# PIC32CZ4010CA80144 device description
Architecture: CORTEX-M7; Family: PIC32C; Series: PIC32CZCA80
Registers are 32-bit, read-write, reset 0x0 unless marked. A register's access mark holds for its fields unless they carry their own. Offsets are from the block's base; [hi:lo] are bit positions; {n}, {i} and the like mark numbered series; 'fields as' and 'values as' point back to an identical list.

## EIC — External Interrupt Controller
Instances: EIC 0x44800000
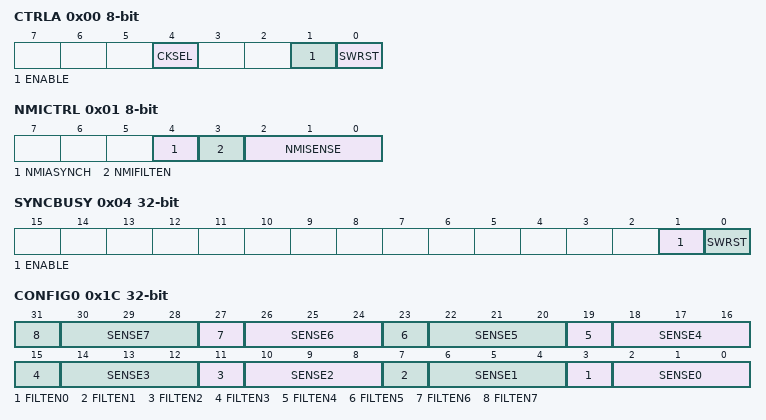
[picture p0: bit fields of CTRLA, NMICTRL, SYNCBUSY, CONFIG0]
0x00 CTRLA 8-bit — Control A
  [4] CKSEL — Clock Selection
    0=CLK_GCLK (Clocked by GCLK); 1=CLK_ULP32K (Clocked by ULP32K)
  [1] ENABLE
  [0] SWRST — Software Reset
0x01 NMICTRL 8-bit — Non-Maskable Interrupt Control
  [4] NMIASYNCH — Asynchronous Edge Detection Mode
    0=SYNC (Edge detection is clock synchronously operated); 1=ASYNC (Edge detection is clock asynchronously operated)
  [3] NMIFILTEN — Non-Maskable Interrupt Filter Enable
  [2:0] NMISENSE — Non-Maskable Interrupt Sense Configuration
    0=NONE (No detection); 1=RISE (Rising-edge detection); 2=FALL (Falling-edge detection); 3=BOTH (Both-edges detection); 4=HIGH (High-level detection); 5=LOW (Low-level detection)
0x02 NMIFLAG 16-bit (atomic clear) — Non-Maskable Interrupt Flag Status and Clear
  [0] NMI — Non-Maskable Interrupt
0x04 SYNCBUSY ro — Synchronization Busy
  [1] ENABLE — Enable Synchronization Busy Status
  [0] SWRST — Software Reset Synchronization Busy Status
0x08 EVCTRL — Event Control
  [15:0] EXTINTEO — External Interrupt Event Output Enable
0x0C INTENCLR (atomic clear) — Interrupt Enable Clear
  [15:0] EXTINT — External Interrupt Enable
0x10 INTENSET (atomic set) — Interrupt Enable Set
  [15:0] EXTINT — External Interrupt Enable
0x14 INTFLAG (atomic clear) — Interrupt Flag Status and Clear
  [15:0] EXTINT — External Interrupt
0x18 ASYNCH — External Interrupt Asynchronous Mode
  [15:0] ASYNCH — Asynchronous Edge Detection Mode
    values as NMICTRL.NMIASYNCH
0x1C CONFIG0 — External Interrupt Sense Configuration
  [4n+3] FILTEN{n} (n=0..7) — Filter Enable {n}
  [4n+2:4n] SENSE{n} (n=0..7) — Input Sense Configuration {n}
    0=NONE (No detection); 1=RISE (Rising edge detection); 2=FALL (Falling edge detection); 3=BOTH (Both edges detection); 4=HIGH (High level detection); 5=LOW (Low level detection)
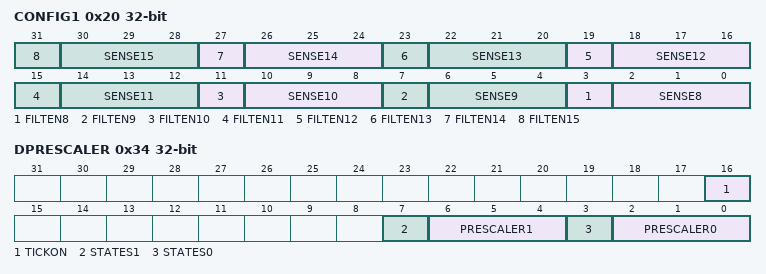
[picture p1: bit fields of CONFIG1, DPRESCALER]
0x20 CONFIG1 — External Interrupt Sense Configuration
  [4n-29] FILTEN{n} (n=8..15) — Filter Enable {n}
  [4n-30:4n-32] SENSE{n} (n=8..15) — Input Sense Configuration {n}
    values as CONFIG0.SENSE0
0x30 DEBOUNCEN — Debouncer Enable
  [15:0] DEBOUNCEN
0x34 DPRESCALER — Debouncer Prescaler
  [16] TICKON — Pin Sampler frequency selection
    0=CLK_GCLK_EIC (Clocked by GCLK); 1=CLK_LFREQ (Clocked by Low Frequency Clock)
  [7] STATES1 — Debouncer number of states
    0=LFREQ3 (3 low frequency samples); 1=LFREQ7 (7 low frequency samples)
  [6:4] PRESCALER1 — Debouncer Prescaler
    0=DIV2 (EIC clock divided by 2); 1=DIV4 (EIC clock divided by 4); 2=DIV8 (EIC clock divided by 8); 3=DIV16 (EIC clock divided by 16); 4=DIV32 (EIC clock divided by 32); 5=DIV64 (EIC clock divided by 64); 6=DIV128 (EIC clock divided by 128); 7=DIV256 (EIC clock divided by 256)
  [3] STATES0 — Debouncer number of states
    values as STATES1
  [2:0] PRESCALER0 — Debouncer Prescaler
    values as PRESCALER1
0x38 PINSTATE ro
  [15:0] PINSTATE

## ETM — Embedded Trace Macrocell
Instances: ETM 0xE0041000
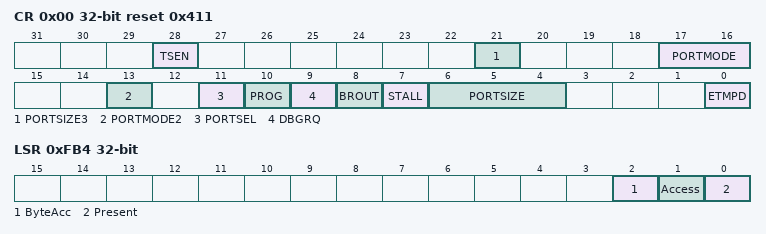
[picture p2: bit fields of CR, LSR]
0x00 CR reset 0x411 — ETM Main Control Register
  [28] TSEN — TimeStamp Enable
  [21] PORTSIZE3 — Port Size bit 3
  [17:16] PORTMODE — Port Mode bits 1:0
  [13] PORTMODE2 — Port Mode bit 2
  [11] PORTSEL — ETM Port Select
  [10] PROG — ETM Programming
  [9] DBGRQ — Debug Request Control
  [8] BROUT — Branch Output
  [7] STALL — Stall Processor
  [6:4] PORTSIZE — Port Size bits 2:0
  [0] ETMPD — ETM Power Down
0x04 CCR ro reset 0x8C802000 — ETM Configuration Code Register
0x08 TRIGGER reset not defined — ETM Trigger Event Register
0x10 SR reset not defined — ETM Status Register
0x14 SCR ro reset 0x20D09 (atomic clear of SR) — ETM System Configuration Register
0x20 TEEVR reset not defined — ETM TraceEnable Event Register
0x24 TECR1 reset not defined — ETM TraceEnable Control 1 Register
0x28 FFLR reset not defined — ETM FIFO Full Level Register
0x140 CNTRLDVR1 reset not defined — ETM Free-running Counter Reload Value
0x1E0 SYNCFR ro reset 0x400 — ETM Synchronization Frequency Register
0x1E4 IDR ro reset 0x4114F250 — ETM ID Register
0x1E8 CCER ro reset 0x18541800 — ETM Configuration Code Extension Register
0x1F0 TESSEICR reset not defined — ETM TraceEnable Start/Stop EmbeddedICE Control Register
0x1F8 TSEVT reset not defined — ETM TimeStamp Event Register
0x200 TRACEIDR — ETM CoreSight Trace ID Register
0x208 IDR2 ro — ETM ID Register 2
0x314 PDSR ro reset 0x1 — ETM Device Power-Down Status Register
0xEE0 ITMISCIN ro reset not defined — ETM Integration Test Miscellaneous Inputs
0xEE8 ITTRIGOUT wo reset not defined — ETM Integration Test Trigger Out
0xEF0 ITATBCTR2 ro reset not defined — ETM Integration Test ATB Control 2
0xEF8 ITATBCTR0 wo reset not defined — ETM Integration Test ATB Control 0
0xF00 ITCTRL — ETM Integration Mode Control Register
  [0] INTEGRATION
0xFA0 CLAIMSET reset not defined (atomic set) — ETM Claim Tag Set Register
0xFA4 CLAIMCLR reset not defined (atomic clear) — ETM Claim Tag Clear Register
0xFB0 LAR wo reset not defined — ETM Lock Access Register
0xFB4 LSR ro reset not defined — ETM Lock Status Register
  [2] ByteAcc, [1] Access, [0] Present
0xFB8 AUTHSTATUS ro reset not defined — ETM Authentication Status Register
0xFCC DEVTYPE ro reset 0x13 — ETM CoreSight Device Type Register
0xFD0 PIDR4 ro reset 0x4 — ETM Peripheral Identification Register #4
{0xFC0+4i} PIDR{i} ro (i=5..7) — ETM Peripheral Identification Register #{i}
0xFE0 PIDR0 ro reset 0x25 — ETM Peripheral Identification Register #0
0xFE4 PIDR1 ro reset 0xB9 — ETM Peripheral Identification Register #1
0xFE8 PIDR2 ro reset 0xB — ETM Peripheral Identification Register #2
0xFEC PIDR3 ro — ETM Peripheral Identification Register #3
0xFF0 CIDR0 ro reset 0xD — ETM Component Identification Register #0
0xFF4 CIDR1 ro reset 0x90 — ETM Component Identification Register #1
0xFF8 CIDR2 ro reset 0x5 — ETM Component Identification Register #2
0xFFC CIDR3 ro reset 0xB1 — ETM Component Identification Register #3

## Notices in the file
Copyright (c) 2021 Microchip Technology Inc.
SPDX-License-Identifier: Apache-2.0
Licensed under the Apache License, Version 2.0 (the "License");
you may not use this file except in compliance with the License.
You may obtain a copy of the License at
http://www.apache.org/licenses/LICENSE-2.0
Unless required by applicable law or agreed to in writing, software
distributed under the License is distributed on an "AS IS" BASIS,
WITHOUT WARRANTIES OR CONDITIONS OF ANY KIND, either express or implied.
See the License for the specific language governing permissions and
limitations under the License.
